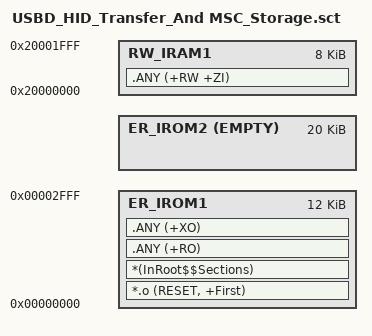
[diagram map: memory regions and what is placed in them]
; *************************************************************
; *** Scatter-Loading Description File generated by uVision ***
; *************************************************************

LR_IROM1 0x00000000 0x0008000  {    ; load region size_region
  ER_IROM1 0x00000000 0x00003000  {  ; load address = execution address
   *.o (RESET, +First)
   *(InRoot$$Sections)
   .ANY (+RO)
   .ANY (+XO)
  }

  ER_IROM2 +0 EMPTY 0x5000 { ;Create a free space for RAM disk
							 ;Hardfault fault may raise while PC doing formatting
  						     ;if target device is with insufficient RAM
  }

  RW_IRAM1 0x20000000 0x00002000  {  ; RW data
   .ANY (+RW +ZI)
  }

}

